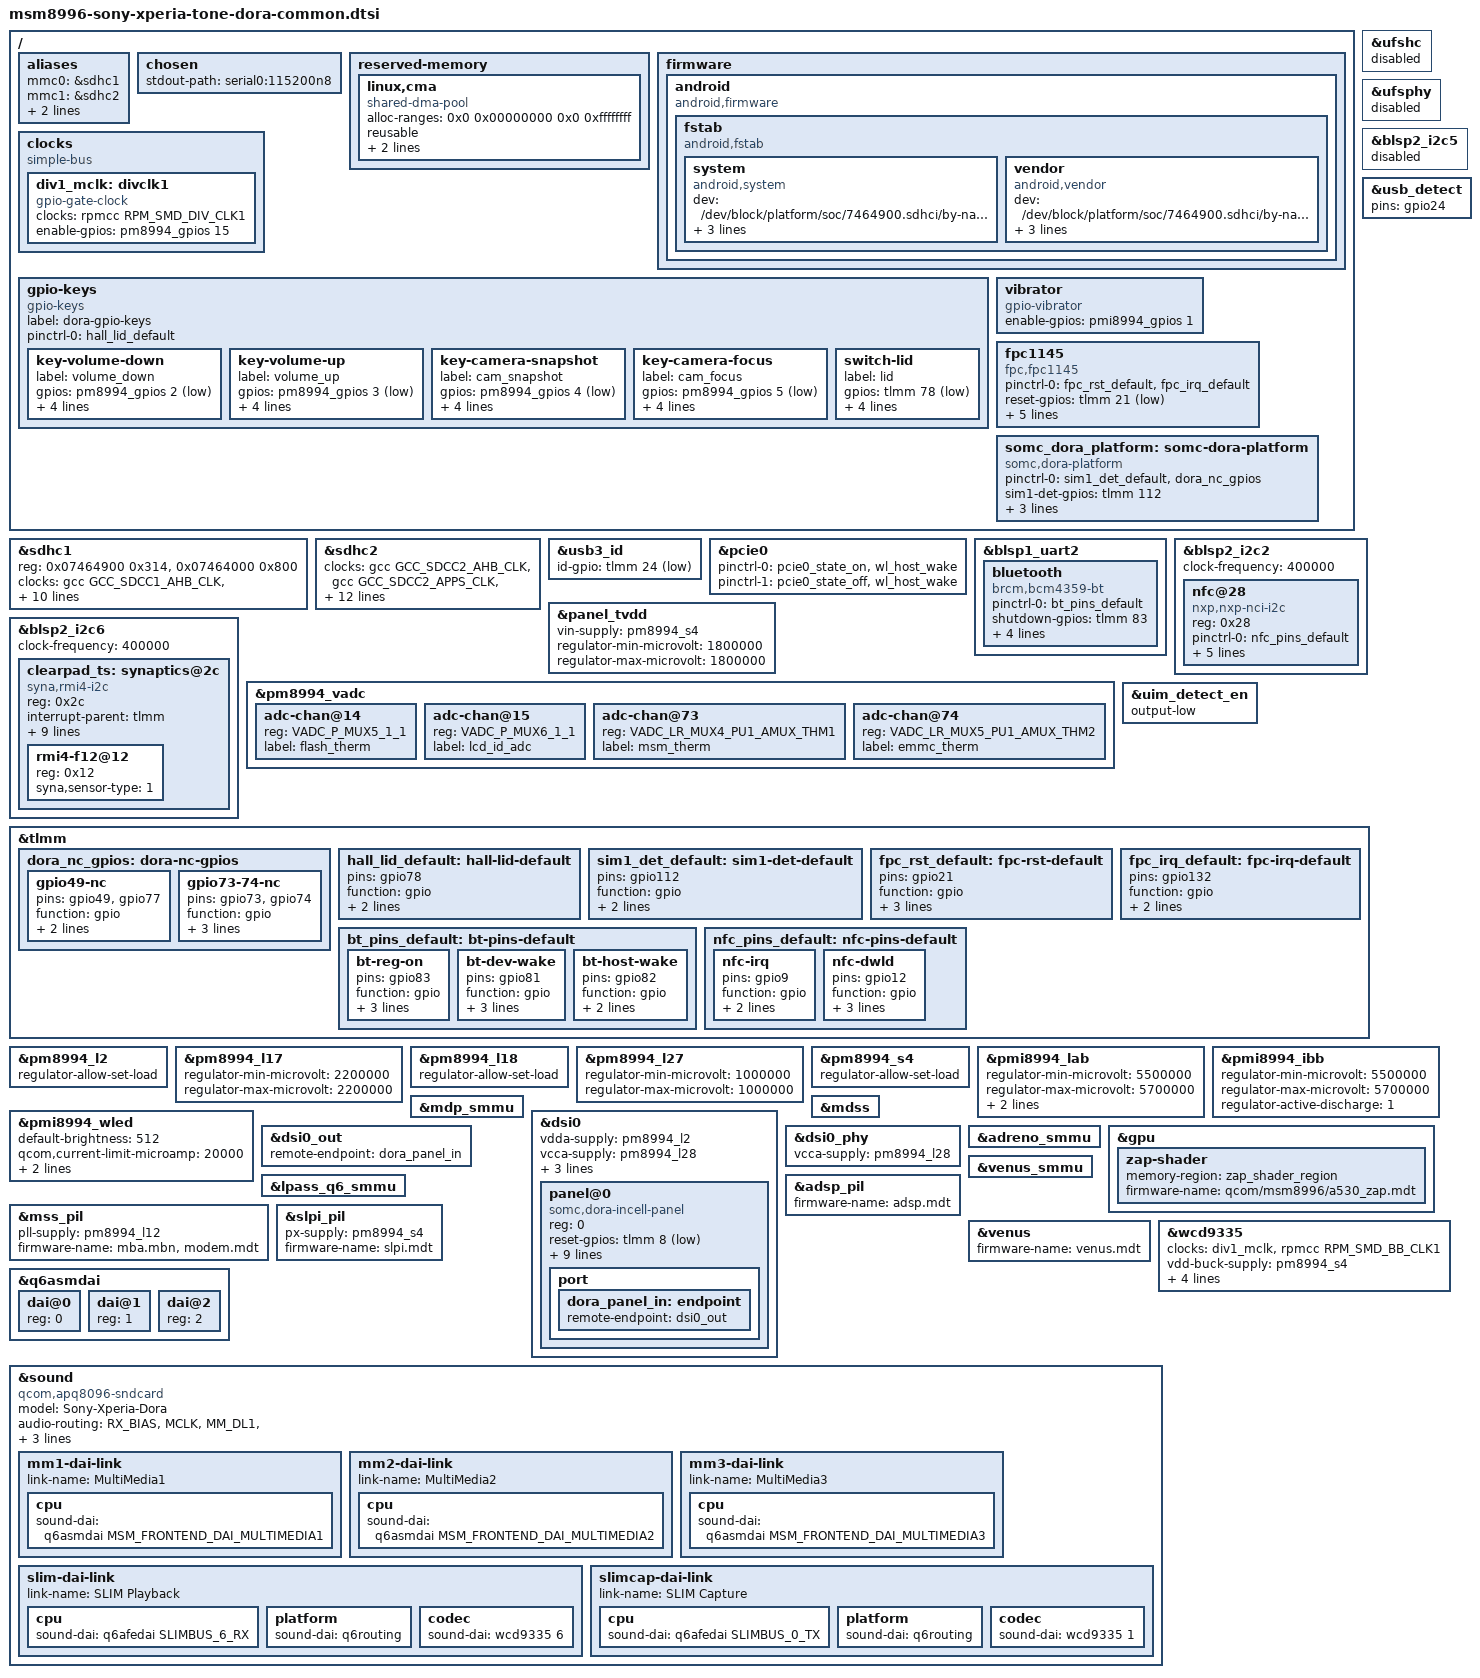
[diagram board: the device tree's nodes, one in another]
// SPDX-License-Identifier: BSD-3-Clause
/*
 * Sony Xperia X Performance (dora: F8131 Single SIM / F8132 Dual SIM)
 * Hardware platform & peripherals ported from Sony Linux 4.4.302 (0c295b15b6d0)
 * to Linux 5.15.
 */

#include <dt-bindings/clock/qcom,gcc-msm8996.h>
#include <dt-bindings/clock/qcom,rpmcc.h>
#include <dt-bindings/iio/qcom,spmi-vadc.h>
#include <dt-bindings/input/linux-event-codes.h>
#include <dt-bindings/sound/qcom,q6afe.h>
#include <dt-bindings/sound/qcom,q6asm.h>

/delete-node/ &tof_sensor;
/delete-node/ &pm8994_l11;
/delete-node/ &pm8994_l14;

/ {
	aliases {
		mmc0 = &sdhc1;
		mmc1 = &sdhc2;
		serial0 = &blsp2_uart2;
		serial1 = &blsp1_uart2;
	};

	chosen {
		stdout-path = "serial0:115200n8";
	};

	reserved-memory {
		/* Enlarge default CMA pool to 64 MiB as in Sony 4.4 msm8996-tone-dora-common.dtsi */
		linux,cma {
			compatible = "shared-dma-pool";
			alloc-ranges = <0x0 0x00000000 0x0 0xffffffff>;
			reusable;
			size = <0x0 0x4000000>;
			linux,cma-default;
		};
	};

	/* Legacy early-mount DT fstab for LineageOS / Sony oem->vendor SquashFS layout */
	firmware {
		android {
			compatible = "android,firmware";
			fstab {
				compatible = "android,fstab";
				system {
					compatible = "android,system";
					dev = "/dev/block/platform/soc/7464900.sdhci/by-name/system";
					type = "ext4";
					mnt_flags = "ro,barrier=1";
					fsmgr_flags = "wait";
					status = "okay";
				};
				vendor {
					compatible = "android,vendor";
					dev = "/dev/block/platform/soc/7464900.sdhci/by-name/oem";
					type = "squashfs";
					mnt_flags = "ro,barrier=1";
					fsmgr_flags = "wait";
					status = "okay";
				};
			};
		};
	};

	clocks {
		compatible = "simple-bus";

		/* WCD9335 Tasha 9.6 MHz MCLK gated by PM8994 GPIO 15 (PM_DIVCLK1) */
		div1_mclk: divclk1 {
			compatible = "gpio-gate-clock";
			clocks = <&rpmcc RPM_SMD_DIV_CLK1>;
			#clock-cells = <0>;
			enable-gpios = <&pm8994_gpios 15 GPIO_ACTIVE_HIGH>;
		};
	};

	gpio-keys {
		compatible = "gpio-keys";
		label = "dora-gpio-keys";
		pinctrl-names = "default";
		pinctrl-0 = <&hall_lid_default>;

		key-volume-down {
			label = "volume_down";
			gpios = <&pm8994_gpios 2 GPIO_ACTIVE_LOW>;
			linux,input-type = <EV_KEY>;
			linux,code = <KEY_VOLUMEDOWN>;
			debounce-interval = <15>;
			wakeup-source;
		};

		key-volume-up {
			label = "volume_up";
			gpios = <&pm8994_gpios 3 GPIO_ACTIVE_LOW>;
			linux,input-type = <EV_KEY>;
			linux,code = <KEY_VOLUMEUP>;
			debounce-interval = <15>;
			wakeup-source;
		};

		key-camera-snapshot {
			label = "cam_snapshot";
			gpios = <&pm8994_gpios 4 GPIO_ACTIVE_LOW>;
			linux,input-type = <EV_KEY>;
			linux,code = <KEY_CAMERA>;
			debounce-interval = <15>;
			wakeup-source;
		};

		key-camera-focus {
			label = "cam_focus";
			gpios = <&pm8994_gpios 5 GPIO_ACTIVE_LOW>;
			linux,input-type = <EV_KEY>;
			linux,code = <KEY_CAMERA_FOCUS>;
			debounce-interval = <15>;
			wakeup-source;
		};

		/* Rohm BU520x1NVX Hall effect cover sensor on TLMM GPIO 78 */
		switch-lid {
			label = "lid";
			gpios = <&tlmm 78 GPIO_ACTIVE_LOW>;
			linux,input-type = <EV_SW>;
			linux,code = <SW_LID>;
			debounce-interval = <120>;
			wakeup-source;
		};
	};

	/* LDO / GPIO Vibrator on PMI8994 GPIO 1 (Sony 4.4 ldo_vibrator) */
	vibrator {
		compatible = "gpio-vibrator";
		enable-gpios = <&pmi8994_gpios 1 GPIO_ACTIVE_HIGH>;
	};

	/* FPC1145 / FPC1020 side-button fingerprint sensor (SPI0 owned by QSEE TZ) */
	fpc1145 {
		compatible = "fpc,fpc1145", "fpc,fpc1020";
		pinctrl-names = "default";
		pinctrl-0 = <&fpc_rst_default &fpc_irq_default>;
		reset-gpios = <&tlmm 21 GPIO_ACTIVE_LOW>;
		irq-gpios = <&tlmm 132 GPIO_ACTIVE_HIGH>;
		vcc_spi-supply = <&pm8994_s4>;
		vdd_ana-supply = <&pm8994_l18>;
		vdd_io-supply = <&pm8994_l18>;
		wakeup-source;
		status = "okay";
	};

	/* Sony Dora platform bridge: SIM1 detect, remoteproc boot & Clearpad wakeup */
	somc_dora_platform: somc-dora-platform {
		compatible = "somc,dora-platform";
		pinctrl-names = "default";
		pinctrl-0 = <&sim1_det_default &dora_nc_gpios>;
		sim1-det-gpios = <&tlmm 112 GPIO_ACTIVE_HIGH>;
		somc,adsp-rproc = <&adsp_pil>;
		somc,slpi-rproc = <&slpi_pil>;
		somc,touch-i2c = <&clearpad_ts>;
		status = "okay";
	};
};

/*
 * Dora uses eMMC 5.1 on sdhc1 (7464900.sdhci), not UFS:
 *  - Expand hc_mem window from 0x11c to 0x314 so sdhci_msm_v4 vendor registers
 *    (0x11c..0x1bc: core_vendor_spec_capabilities0..core_ddr_config) are mapped.
 *  - Wire GCC_SDCC1_BCR hardware reset so sdhci_msm_gcc_reset() clears S1
 *    bootloader PIO state prior to ADMA/HS400 initialization.
 *  - Use RPM_SMD_XO_CLK_SRC for 19.2 MHz XO calibration clock.
 */
&sdhc1 {
	status = "okay";
	reg = <0x07464900 0x314>, <0x07464000 0x800>;
	reg-names = "hc_mem", "core_mem";
	clocks = <&gcc GCC_SDCC1_AHB_CLK>,
		 <&gcc GCC_SDCC1_APPS_CLK>,
		 <&rpmcc RPM_SMD_XO_CLK_SRC>;
	clock-names = "iface", "core", "xo";
	resets = <&gcc GCC_SDCC1_BCR>;
	vmmc-supply = <&pm8994_l20>;
	vqmmc-supply = <&pm8994_s4>;
	bus-width = <8>;
	non-removable;
	mmc-ddr-1_8v;
	mmc-hs200-1_8v;
	mmc-hs400-1_8v;
};

/*
 * MicroSD + F8132 Dual-SIM hybrid UIM2/SD tray on sdhc2 (74a4900.sdhci):
 *  - cd-gpios (TLMM 40, ACTIVE_HIGH): tray closed detection
 *  - uim2-gpios (TLMM 29, ACTIVE_HIGH): asserted high by MMC core only when
 *    tray is closed and no SD card responds, routing UIM2 to modem on F8132.
 */
&sdhc2 {
	status = "okay";
	clocks = <&gcc GCC_SDCC2_AHB_CLK>,
		 <&gcc GCC_SDCC2_APPS_CLK>,
		 <&rpmcc RPM_SMD_XO_CLK_SRC>;
	clock-names = "iface", "core", "xo";
	resets = <&gcc GCC_SDCC2_BCR>;
	pinctrl-names = "default", "sleep";
	pinctrl-0 = <&sdc2_state_on &tray_det_pin &uim_detect_en>;
	pinctrl-1 = <&sdc2_state_off &tray_det_pin &uim_detect_en>;
	cd-gpios = <&tlmm 40 GPIO_ACTIVE_HIGH>;
	uim2-gpios = <&tlmm 29 GPIO_ACTIVE_HIGH>;
	vmmc-supply = <&pm8994_l21>;
	vqmmc-supply = <&pm8994_l13>;
	no-sdio;
	no-mmc;
};

&ufshc {
	status = "disabled";
};

&ufsphy {
	status = "disabled";
};

/* Dora uses Micro-USB 2.0 OTG (ID on GPIO 24), no USB-C FUSB301 on BLSP2 I2C5 */
&blsp2_i2c5 {
	status = "disabled";
};

&usb_detect {
	pins = "gpio24";
};

&usb3_id {
	id-gpio = <&tlmm 24 GPIO_ACTIVE_LOW>;
};

/* Broadcom BCM4359 Wi-Fi PCIe0 + host-wake pinctrl */
&pcie0 {
	status = "okay";
	pinctrl-names = "default", "sleep";
	pinctrl-0 = <&pcie0_state_on &wl_host_wake>;
	pinctrl-1 = <&pcie0_state_off &wl_host_wake>;
};

/* Broadcom BCM4359 Bluetooth H4/BCM serdev on BLSP1 UART2 (serial@7570000) */
&blsp1_uart2 {
	status = "okay";

	bluetooth {
		compatible = "brcm,bcm4359-bt", "brcm,bcm4349-bt", "brcm,bcm43438-bt";
		pinctrl-names = "default";
		pinctrl-0 = <&bt_pins_default>;
		shutdown-gpios = <&tlmm 83 GPIO_ACTIVE_HIGH>;
		device-wakeup-gpios = <&tlmm 81 GPIO_ACTIVE_HIGH>;
		host-wakeup-gpios = <&tlmm 82 GPIO_ACTIVE_HIGH>;
		vddio-supply = <&pm8994_s4>;
		max-speed = <3000000>;
	};
};

/* NXP PN547 / PN548 NFC controller on BLSP2 I2C2 (0x75b6000 @ 0x28) */
&blsp2_i2c2 {
	status = "okay";
	clock-frequency = <400000>;

	nfc@28 {
		compatible = "nxp,nxp-nci-i2c";
		reg = <0x28>;
		pinctrl-names = "default";
		pinctrl-0 = <&nfc_pins_default>;
		interrupt-parent = <&tlmm>;
		interrupts = <9 IRQ_TYPE_EDGE_RISING>;
		enable-gpios = <&pm8994_gpios 7 GPIO_ACTIVE_HIGH>;
		firmware-gpios = <&tlmm 12 GPIO_ACTIVE_HIGH>;
		wakeup-source;
	};
};

/* Touch I/O 1.8V load switch on GPIO 50 (tp_vddio_en) fed by pm8994_s4 */
&panel_tvdd {
	vin-supply = <&pm8994_s4>;
	regulator-min-microvolt = <1800000>;
	regulator-max-microvolt = <1800000>;
};

/* Synaptics Clearpad S3320 In-Cell Touchscreen on BLSP2 I2C6 (0x75ba000 @ 0x2c) */
&blsp2_i2c6 {
	status = "okay";
	clock-frequency = <400000>;

	clearpad_ts: synaptics@2c {
		compatible = "syna,rmi4-i2c";
		reg = <0x2c>;
		#address-cells = <1>;
		#size-cells = <0>;
		interrupt-parent = <&tlmm>;
		interrupts = <125 IRQ_TYPE_EDGE_FALLING>;
		pinctrl-names = "default", "sleep";
		pinctrl-0 = <&touch_int_n &ts_reset_n>;
		pinctrl-1 = <&touch_int_sleep &ts_reset_n>;
		reset-gpios = <&tlmm 89 GPIO_ACTIVE_LOW>;
		vdd-supply = <&pm8994_l22>;
		vio-supply = <&panel_tvdd>;
		syna,reset-delay-ms = <60>;
		syna,startup-delay-ms = <100>;
		wakeup-source;

		/delete-node/ rmi4-f11@11;

		rmi4-f12@12 {
			reg = <0x12>;
			syna,sensor-type = <1>;
		};
	};
};

/* PM8994 VADC channels for LCD_ID_ADC (MPP2 -> AMUX6) and Sony Thermistor inputs */
&pm8994_vadc {
	adc-chan@14 {
		reg = <VADC_P_MUX5_1_1>;
		label = "flash_therm";
	};

	adc-chan@15 {
		reg = <VADC_P_MUX6_1_1>;
		label = "lcd_id_adc";
	};

	adc-chan@73 {
		reg = <VADC_LR_MUX4_PU1_AMUX_THM1>;
		label = "msm_therm";
	};

	adc-chan@74 {
		reg = <VADC_LR_MUX5_PU1_AMUX_THM2>;
		label = "emmc_therm";
	};
};

&uim_detect_en {
	output-low;
};

&tlmm {
	dora_nc_gpios: dora-nc-gpios {
		gpio49-nc {
			pins = "gpio49", "gpio77";
			function = "gpio";
			drive-strength = <2>;
			bias-pull-down;
		};

		gpio73-74-nc {
			pins = "gpio73", "gpio74";
			function = "gpio";
			drive-strength = <2>;
			bias-disable;
			output-low;
		};
	};

	hall_lid_default: hall-lid-default {
		pins = "gpio78";
		function = "gpio";
		drive-strength = <2>;
		bias-pull-up;
	};

	sim1_det_default: sim1-det-default {
		pins = "gpio112";
		function = "gpio";
		drive-strength = <2>;
		bias-disable;
	};

	fpc_rst_default: fpc-rst-default {
		pins = "gpio21";
		function = "gpio";
		drive-strength = <2>;
		bias-disable;
		output-low;
	};

	fpc_irq_default: fpc-irq-default {
		pins = "gpio132";
		function = "gpio";
		drive-strength = <2>;
		bias-pull-down;
	};

	bt_pins_default: bt-pins-default {
		bt-reg-on {
			pins = "gpio83";
			function = "gpio";
			drive-strength = <2>;
			bias-disable;
			output-low;
		};

		bt-dev-wake {
			pins = "gpio81";
			function = "gpio";
			drive-strength = <2>;
			bias-disable;
			output-low;
		};

		bt-host-wake {
			pins = "gpio82";
			function = "gpio";
			drive-strength = <2>;
			bias-pull-down;
		};
	};

	nfc_pins_default: nfc-pins-default {
		nfc-irq {
			pins = "gpio9";
			function = "gpio";
			drive-strength = <2>;
			bias-pull-down;
		};

		nfc-dwld {
			pins = "gpio12";
			function = "gpio";
			drive-strength = <2>;
			bias-disable;
			output-low;
		};
	};
};

/* Dora-specific PM8994 regulator limits from Sony 4.4 msm8996-tone-dora-common.dtsi */
&pm8994_l2 {
	regulator-allow-set-load;
};

&pm8994_l17 {
	regulator-min-microvolt = <2200000>;
	regulator-max-microvolt = <2200000>;
};

&pm8994_l18 {
	regulator-allow-set-load;
};

&pm8994_l27 {
	regulator-min-microvolt = <1000000>;
	regulator-max-microvolt = <1000000>;
};

&pm8994_s4 {
	regulator-allow-set-load;
};

&pmi8994_lab {
	regulator-min-microvolt = <5500000>;
	regulator-max-microvolt = <5700000>;
	regulator-active-discharge = <1>;
	qcom,soft-start-us = <800>;
};

&pmi8994_ibb {
	regulator-min-microvolt = <5500000>;
	regulator-max-microvolt = <5700000>;
	regulator-active-discharge = <1>;
};

/*
 * Disable pmi8994.dtsi default qcom,cabc: Dora panels disable CABC PWM (0x55 0x00),
 * so leaving qcom,cabc enabled gates all 3 WLED strings to 0% duty cycle.
 */
&pmi8994_wled {
	status = "okay";
	/delete-property/ qcom,cabc;
	default-brightness = <512>;
	qcom,current-limit-microamp = <20000>;
	qcom,num-strings = <3>;
	qcom,enabled-strings = <0 1 2>;
};

&mdp_smmu {
	status = "okay";
};

&mdss {
	status = "okay";
};

&dsi0 {
	status = "okay";
	vdda-supply = <&pm8994_l2>;
	vcca-supply = <&pm8994_l28>;
	vddio-supply = <&pm8994_s4>;
	pinctrl-names = "default";
	pinctrl-0 = <&disp_reset_n_gpio &mdp_vsync_p_gpio &lcd_vddio_en>;

	panel@0 {
		compatible = "somc,dora-incell-panel", "somc,auo_synaptics_cmd_4_panel";
		reg = <0>;
		reset-gpios = <&tlmm 8 GPIO_ACTIVE_LOW>;
		vddio-gpios = <&tlmm 51 GPIO_ACTIVE_HIGH>;
		vddio-supply = <&pm8994_s4>;
		lab-supply = <&pmi8994_lab>;
		ibb-supply = <&pmi8994_ibb>;
		touch-avdd-supply = <&pm8994_l22>;
		io-channels = <&pm8994_vadc VADC_P_MUX6_1_1>;
		io-channel-names = "lcd-id";
		backlight = <&pmi8994_wled>;

		/*
		 * Preserved Sony 4.4 dsi-panel-dora.dtsi ADC lookup reference table:
		 *   Panel 9 (Sharp ID9): <0 57000>
		 *   Panel 8 (LGD ID8):   <215000 256000>
		 *   Panel 6 (JDI ID6):   <353000 653000>
		 *   Panel 4 (AUO ID4):   <1087000 1231000>  [F8132 confirmed: 0x11FFEA / 1179626]
		 *   Panel 3 (Sharp ID3): <1236000 1395000>
		 */
		somc,panel-adc-windows-uv = <
			9 0 57000
			8 215000 256000
			6 353000 653000
			4 1087000 1231000
			3 1236000 1395000
		>;

		port {
			dora_panel_in: endpoint {
				remote-endpoint = <&dsi0_out>;
			};
		};
	};
};

&dsi0_out {
	remote-endpoint = <&dora_panel_in>;
};

&dsi0_phy {
	status = "okay";
	vcca-supply = <&pm8994_l28>;
};

/* Adreno 530 GPU + SMMU + Zap Shader */
&adreno_smmu {
	status = "okay";
};

&gpu {
	status = "okay";

	zap-shader {
		memory-region = <&zap_shader_region>;
		firmware-name = "qcom/msm8996/a530_zap.mdt";
	};
};

/* Remoteproc subsystems: Modem (MPSS), Audio DSP (LPASS/ADSP), Sensor DSP (SLPI), Venus Video */
&lpass_q6_smmu {
	status = "okay";
};

&adsp_pil {
	status = "okay";
	firmware-name = "adsp.mdt";
};

&mss_pil {
	status = "okay";
	pll-supply = <&pm8994_l12>;
	firmware-name = "mba.mbn", "modem.mdt";
};

&slpi_pil {
	status = "okay";
	px-supply = <&pm8994_s4>;
	firmware-name = "slpi.mdt";
};

&venus_smmu {
	status = "okay";
};

&venus {
	status = "okay";
	firmware-name = "venus.mdt";
};

/* Audio: Qualcomm WCD9335 (Tasha) SLIMbus codec + Q6DSP routing */
&wcd9335 {
	clock-names = "mclk", "slimbus";
	clocks = <&div1_mclk>, <&rpmcc RPM_SMD_BB_CLK1>;
	vdd-buck-supply = <&pm8994_s4>;
	vdd-buck-sido-supply = <&pm8994_s4>;
	vdd-tx-supply = <&pm8994_s4>;
	vdd-rx-supply = <&pm8994_s4>;
	vdd-io-supply = <&pm8994_s4>;
};

&q6asmdai {
	dai@0 {
		reg = <0>;
	};
	dai@1 {
		reg = <1>;
	};
	dai@2 {
		reg = <2>;
	};
};

&sound {
	compatible = "qcom,apq8096-sndcard";
	model = "Sony-Xperia-Dora";
	audio-routing =
		"RX_BIAS", "MCLK",
		"MM_DL1", "MultiMedia1 Playback",
		"MM_DL2", "MultiMedia2 Playback",
		"MultiMedia3 Capture", "MM_UL3";

	mm1-dai-link {
		link-name = "MultiMedia1";
		cpu {
			sound-dai = <&q6asmdai MSM_FRONTEND_DAI_MULTIMEDIA1>;
		};
	};

	mm2-dai-link {
		link-name = "MultiMedia2";
		cpu {
			sound-dai = <&q6asmdai MSM_FRONTEND_DAI_MULTIMEDIA2>;
		};
	};

	mm3-dai-link {
		link-name = "MultiMedia3";
		cpu {
			sound-dai = <&q6asmdai MSM_FRONTEND_DAI_MULTIMEDIA3>;
		};
	};

	slim-dai-link {
		link-name = "SLIM Playback";
		cpu {
			sound-dai = <&q6afedai SLIMBUS_6_RX>;
		};
		platform {
			sound-dai = <&q6routing>;
		};
		codec {
			sound-dai = <&wcd9335 6>;
		};
	};

	slimcap-dai-link {
		link-name = "SLIM Capture";
		cpu {
			sound-dai = <&q6afedai SLIMBUS_0_TX>;
		};
		platform {
			sound-dai = <&q6routing>;
		};
		codec {
			sound-dai = <&wcd9335 1>;
		};
	};
};
